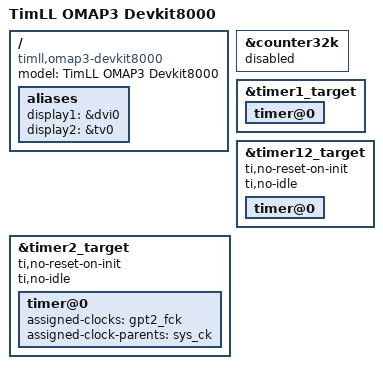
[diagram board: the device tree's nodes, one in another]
// SPDX-License-Identifier: GPL-2.0-only
/*
 * Author: Anthoine Bourgeois <anthoine.bourgeois@gmail.com>
 */
/dts-v1/;

#include "omap3-devkit8000-common.dtsi"
/ {
	model = "TimLL OMAP3 Devkit8000";
	compatible = "timll,omap3-devkit8000", "ti,omap3430", "ti,omap3";

	aliases {
		display1 = &dvi0;
		display2 = &tv0;
	};
};

/* Unusable as clocksource because of unreliable oscillator */
&counter32k {
	status = "disabled";
};

/* Unusable as clockevent because if unreliable oscillator, allow to idle */
&timer1_target {
	/delete-property/ti,no-reset-on-init;
	/delete-property/ti,no-idle;
	timer@0 {
		/delete-property/ti,timer-alwon;
	};
};

/* Preferred always-on timer for clocksource */
&timer12_target {
	ti,no-reset-on-init;
	ti,no-idle;
	timer@0 {
		/* Always clocked by secure_32k_fck */
	};
};

/* Preferred timer for clockevent */
&timer2_target {
	ti,no-reset-on-init;
	ti,no-idle;
	timer@0 {
		assigned-clocks = <&gpt2_fck>;
		assigned-clock-parents = <&sys_ck>;
	};
};
